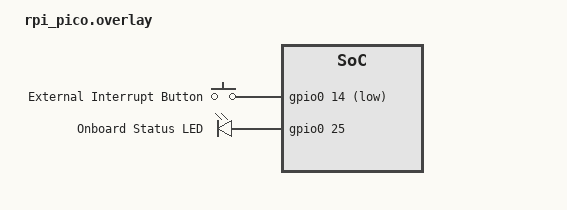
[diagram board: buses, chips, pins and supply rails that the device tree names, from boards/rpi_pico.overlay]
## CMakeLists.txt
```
cmake_minimum_required(VERSION 3.20)

find_package(Zephyr REQUIRED HINTS $ENV{ZEPHYR_BASE})
project(test_kernel_interrupts)

target_sources(app PRIVATE src/main.c)
```

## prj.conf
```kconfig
CONFIG_PRINTK=y

# Core hardware drivers
CONFIG_GPIO=y

# Enable compiler optimizations for production
CONFIG_SPEED_OPTIMIZATIONS=y

# Enable logging infrastructure for safe asynchronous debugging
CONFIG_LOG=y
CONFIG_LOG_DEFAULT_LEVEL=3

CONFIG_SERIAL=y
CONFIG_UART_CONSOLE=y
CONFIG_UART_LINE_CTRL=y
```

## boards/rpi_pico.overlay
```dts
/ {
    aliases {
        sw-isr = &button_isr;
        led-isr = &led_isr;
    };

    buttons {
        compatible = "gpio-keys";
        button_isr: button_0 {
            /* GP14 pin 19 on Raspberry Pi Pico pinout */
            gpios = <&gpio0 14 (GPIO_PULL_UP | GPIO_ACTIVE_LOW)>;
            label = "External Interrupt Button";
        };
    };

    leds {
        compatible = "gpio-leds";
        led_isr: led_0 {
            /* GP25 Onboard LED on Raspberry Pi Pico */
            gpios = <&gpio0 25 GPIO_ACTIVE_HIGH>;
            label = "Onboard Status LED";
        };
    };
};
```

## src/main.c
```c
#include <zephyr/kernel.h>
#include <zephyr/device.h>
#include <zephyr/drivers/gpio.h>
#include <zephyr/logging/log.h>
#include <zephyr/sys/util.h>

LOG_MODULE_REGISTER(main, LOG_LEVEL_INF);

#define DEBOUNCE_TIMEOUT_MS K_MSEC(50)

static const struct gpio_dt_spec button = GPIO_DT_SPEC_GET(DT_ALIAS(sw_isr), gpios);
static const struct gpio_dt_spec led    = GPIO_DT_SPEC_GET(DT_ALIAS(led_isr), gpios);

static struct gpio_callback button_cb_data;
static struct k_work debounce_work;

static void debounce_work_handler(struct k_work *work)
{
    ARG_UNUSED(work);

    if (gpio_pin_get_dt(&button) == 1)
    {
        LOG_INF("Valid Button Interrupt Confirmed. Toggling LED State.");
        gpio_pin_toggle_dt(&led);
    }
}

static void button_pressed_isr(const struct device *port, struct gpio_callback *cb, uint32_t pins)
{
    ARG_UNUSED(port);
    ARG_UNUSED(cb);
    ARG_UNUSED(pins);

    k_work_submit(&debounce_work);
}

int main(void)
{
    int ret;

    LOG_INF("Initializing Raspberry Pi Pico ISR Demo App...");

    if (!gpio_is_ready_dt(&led) || !gpio_is_ready_dt(&button))
    {
        LOG_ERR("Error: Hardware GPIO devices are not ready.");
        return -ENODEV;
    }

    ret = gpio_pin_configure_dt(&led, GPIO_OUTPUT_INACTIVE);
    if (ret < 0)
    {
        LOG_ERR("Failed to configure LED pin: %d", ret);
        return ret;
    }

    ret = gpio_pin_configure_dt(&button, GPIO_INPUT);
    if (ret < 0)
    {
        LOG_ERR("Failed to configure Button pin: %d", ret);
        return ret;
    }

    k_work_init(&debounce_work, debounce_work_handler);

    ret = gpio_pin_interrupt_configure_dt(&button, GPIO_INT_EDGE_TO_ACTIVE);
    if (ret < 0)
    {
        LOG_ERR("Failed to configure Interrupt on Button pin: %d", ret);
        return ret;
    }

    gpio_init_callback(&button_cb_data, button_pressed_isr, BIT(button.pin));
    ret = gpio_add_callback(button.port, &button_cb_data);
    if (ret < 0)
    {
        LOG_ERR("Failed to append runtime GPIO driver callback: %d", ret);
        return ret;
    }

    LOG_INF("System Configuration complete. Awaiting edge-triggered ISR requests.");

    while (1)
    {
        k_sleep(K_FOREVER);
    }

    return 0;
}
```
